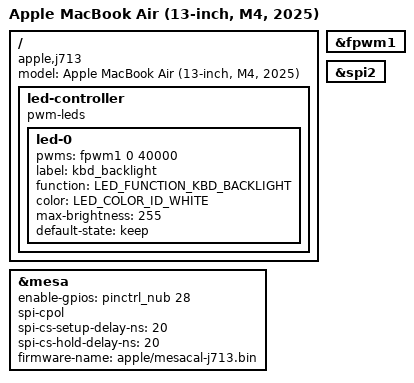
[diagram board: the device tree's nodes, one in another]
// SPDX-License-Identifier: GPL-2.0+ OR MIT
/*
 * Apple MacBook Air (13-inch, M4, 2025)
 *
 * target-type: J713
 *
 * Copyright The Asahi Linux Contributors
 */

/dts-v1/;

#include "t8132.dtsi"
#include "t8132-jxxx.dtsi"
#include <dt-bindings/gpio/gpio.h>
#include <dt-bindings/leds/common.h>

/ {
	compatible = "apple,j713", "apple,t8132", "apple,arm-platform";
	model = "Apple MacBook Air (13-inch, M4, 2025)";

	led-controller {
		compatible = "pwm-leds";
		led-0 {
			pwms = <&fpwm1 0 40000>;
			label = "kbd_backlight";
			function = LED_FUNCTION_KBD_BACKLIGHT;
			color = <LED_COLOR_ID_WHITE>;
			max-brightness = <255>;
			default-state = "keep";
		};
	};
};

&fpwm1 {
	status = "okay";
};

/*
 * Mesa fingerprint sensor on spi2 (J713 ADT /arm-io/spi2/mesa): power on
 * NUB GPIO 28, active high. It answers in mode 2 (CPOL=1, CPHA=0). The
 * data-ready line (AP GPIO 199) is left out, so the driver polls until its
 * trigger is confirmed. Native chip select only.
 */
&spi2 {
	status = "okay";
};

&mesa {
	status = "okay";
	enable-gpios = <&pinctrl_nub 28 GPIO_ACTIVE_HIGH>;
	spi-cpol;
	spi-cs-setup-delay-ns = <20>;
	spi-cs-hold-delay-ns = <20>;
	/* Per-device factory data from this Mac's own iBoot system container. */
	firmware-name = "apple/mesacal-j713.bin";
};
